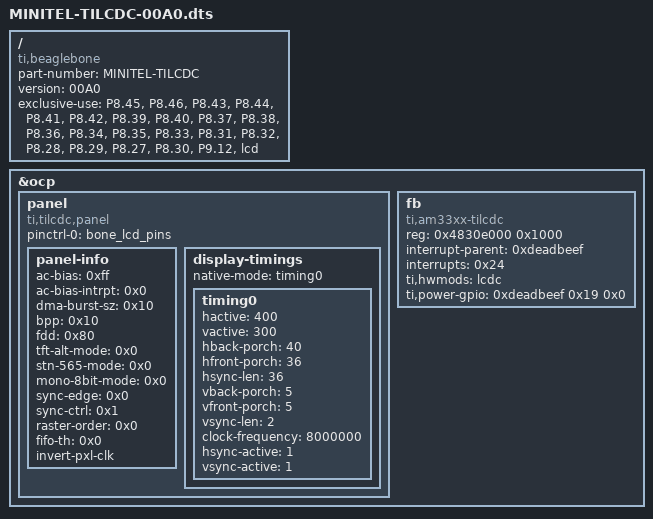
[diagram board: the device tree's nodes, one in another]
/dts-v1/;

/ {
    compatible = "ti,beaglebone", "ti,beaglebone-black";
    part-number = "MINITEL-TILCDC";
    version = "00A0";

    exclusive-use = 
        "P8.45",    /* lcd: lcd_data0 */
        "P8.46",    /* lcd: lcd_data1 */
        "P8.43",    /* lcd: lcd_data2 */
        "P8.44",    /* lcd: lcd_data3 */
        "P8.41",    /* lcd: lcd_data4 */
        "P8.42",    /* lcd: lcd_data5 */
        "P8.39",    /* lcd: lcd_data6 */
        "P8.40",    /* lcd: lcd_data7 */
        "P8.37",    /* lcd: lcd_data8 */
        "P8.38",    /* lcd: lcd_data9 */
        "P8.36",    /* lcd: lcd_data10 */
        "P8.34",    /* lcd: lcd_data11 */
        "P8.35",    /* lcd: lcd_data12 */
        "P8.33",    /* lcd: lcd_data13 */
        "P8.31",    /* lcd: lcd_data14 */
        "P8.32",    /* lcd: lcd_data15 */
        "P8.28",    /* lcd: lcd_pclk        - RD */
        "P8.29",    /* lcd: lcd_hsync       - WR */
        "P8.27",    /* lcd: lcd_vsync       - DC */
        "P8.30",    /* lcd: lcd_ac_bias_en  - CS*/
        "P9.12",    /* Reset */
        "lcd";

    fragment@0 {
        target = <0xam33xx_pinmux>;

        __overlay__ {
            bone_lcd_pins : pinmux_bone_lcd_pins {
                pinctrl-single,pins = <
                    0xa0 0x08   /* lcd_data0 */
                    0xa4 0x08   /* lcd_data1 */
                    0xa8 0x08   /* lcd_data2 */
                    0xac 0x08   /* lcd_data3 */
                    0xb0 0x08   /* lcd_data4 */
                    0xb4 0x08   /* lcd_data5 */
                    0xb8 0x08   /* lcd_data6 */
                    0xbc 0x08   /* lcd_data7 */
                    0xc0 0x08   /* lcd_data8 */
                    0xc4 0x08   /* lcd_data9 */
                    0xc8 0x08   /* lcd_data10 */
                    0xcc 0x08   /* lcd_data11 */
                    0xd0 0x08   /* lcd_data12 */
                    0xd4 0x08   /* lcd_data13 */
                    0xd8 0x08   /* lcd_data14 */
                    0xdc 0x08   /* lcd_data15 */
                    0xe8 0x00   /* lcd_pclk/rd */
                    0xe4 0x00   /* lcd_hsync/wr */
                    0xe0 0x00   /* lcd_vsync/dc */
                    0xec 0x00   /* lcd_ac_bias_en/cs */
                    0x78 0x7F   /* P9_12  60  OUTPUT MODE7 - RS  GPIO1_28 */
                >;
            };
        };
    };

    fragment@2 {
        target = <&ocp>;

        __overlay__ {
            #address-cells = <0x1>;
            #size-cells = <0x1>;

            panel {
                compatible = "ti,tilcdc,panel";
                pinctrl-names = "default";
                pinctrl-0 = <&bone_lcd_pins>;

                panel-info {
                    ac-bias = <0xff>;
                    ac-bias-intrpt = <0x0>;
                    dma-burst-sz = <0x10>;
                    bpp = <0x10>;
                    fdd = <0x80>;
                    tft-alt-mode = <0x0>;
                    stn-565-mode = <0x0>;
                    mono-8bit-mode = <0x0>;
                    sync-edge = <0x0>;
                    sync-ctrl = <0x1>;
                    raster-order = <0x0>;
                    fifo-th = <0x0>;
                    invert-pxl-clk;
                };

                display-timings {
                    native-mode = <&timing0>;
                    // 400x300
                    timing0 {
                        hactive = <400>;
                        vactive = <300>;
                        hback-porch = <40>;
                        hfront-porch = <36>;
                        hsync-len = <36>;
                        vback-porch = <5>;
                        vfront-porch = <5>;
                        vsync-len = <2>; // in frames
                        clock-frequency = <8000000>;
                        hsync-active = <1>;
                        vsync-active = <1>;
                    };
                };
            };

            fb {
                compatible = "ti,am33xx-tilcdc";
                reg = <0x4830e000 0x1000>;
                interrupt-parent = <0xdeadbeef>;
                interrupts = <0x24>;
                ti,hwmods = "lcdc";
                ti,power-gpio = <0xdeadbeef 0x19 0x0>;
            };
        };
    };

};
